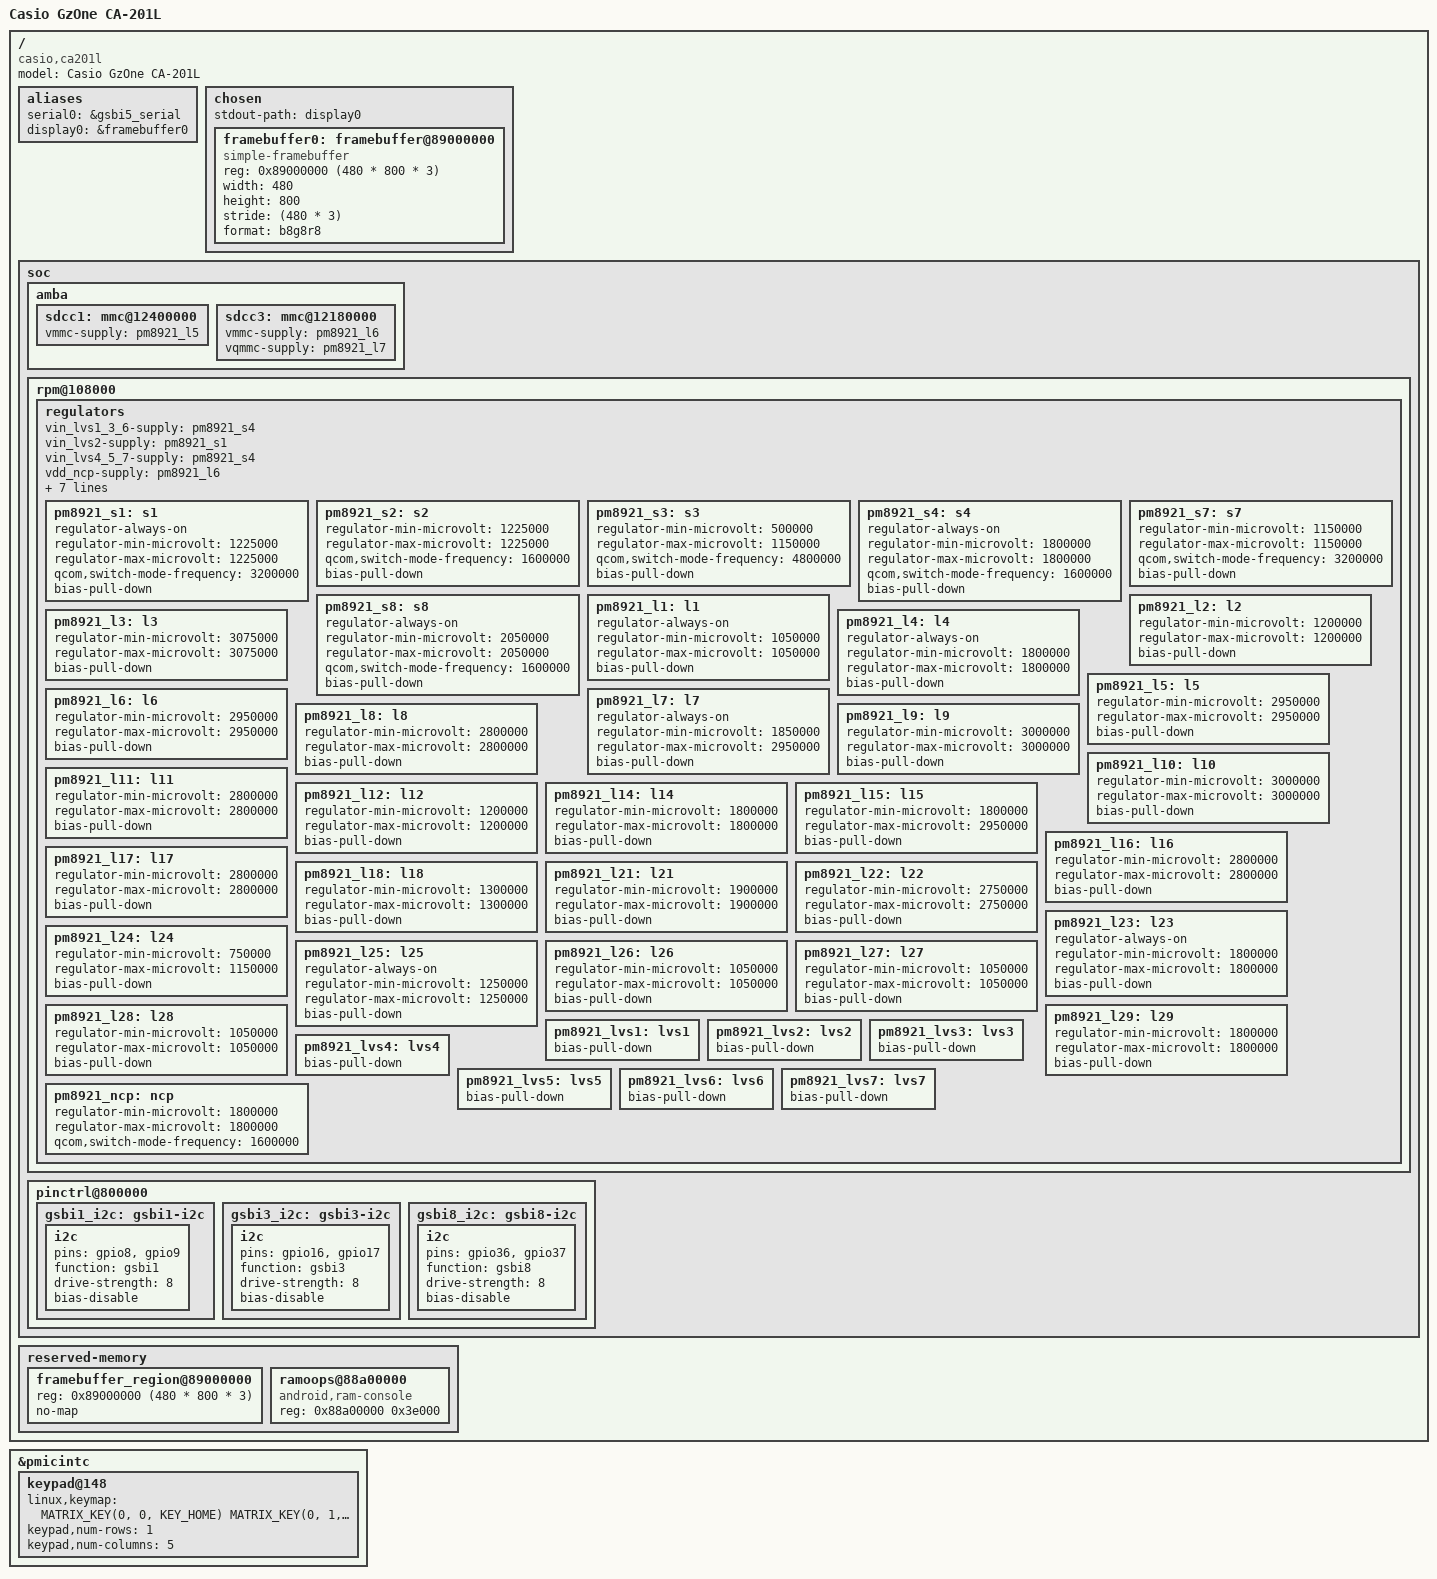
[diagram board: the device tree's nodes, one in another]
// SPDX-License-Identifier: GPL-2.0
#include <dt-bindings/input/input.h>

#include "qcom-msm8960.dtsi"

/*
 * GSBI1 is I2C on this device, remove default mapping
*/
// /delete-node/ &spi@16080000;

/ {
	model = "Casio GzOne CA-201L";
	compatible = "casio,ca201l", "qcom,msm8960";

	aliases {
		serial0 = &gsbi5_serial;
		display0 = &framebuffer0;
	};

	chosen {
		// stdout-path = "serial0:115200n8";
		stdout-path = "display0";

		#address-cells = <1>;
		#size-cells = <1>;
		ranges;

		framebuffer0: framebuffer@89000000 {
			compatible = "simple-framebuffer";
			reg = <0x89000000 (480 * 800 * 3)>;
			width = <480>;
			height = <800>;
			stride = <(480 * 3)>;
			format = "b8g8r8";
		};
	};

	/* Temporary fixed regulator */
	// vsdcc_fixed: vsdcc-regulator {
	// 	compatible = "regulator-fixed";
	// 	regulator-name = "SDCC Power";
	// 	regulator-min-microvolt = <2700000>;
	// 	regulator-max-microvolt = <2700000>;
	// 	regulator-always-on;
	// };

	soc {
		amba {
		 	/* eMMC */
			sdcc1: mmc@12400000 {
				status = "okay";
				vmmc-supply = <&pm8921_l5>;
			};

		 	/* External micro SD card */
			sdcc3: mmc@12180000 {
				status = "okay";
				vmmc-supply = <&pm8921_l6>;
				vqmmc-supply = <&pm8921_l7>;
			};
		};

		rpm@108000 {
			regulators {
				vin_lvs1_3_6-supply = <&pm8921_s4>;
				vin_lvs2-supply = <&pm8921_s1>;
				vin_lvs4_5_7-supply = <&pm8921_s4>;
				vdd_ncp-supply = <&pm8921_l6>;
				vdd_l1_l2_l12_l18-supply = <&pm8921_s4>;
				vdd_l21_l23_l29-supply = <&pm8921_s8>;
				vdd_l24-supply = <&pm8921_s1>;
				vdd_l25-supply = <&pm8921_s1>;
				vdd_l26-supply = <&pm8921_s7>;
				vdd_l27-supply = <&pm8921_s7>;
				vdd_l28-supply = <&pm8921_s7>;

				/* Buck SMPS */
				pm8921_s1: s1 {
					regulator-always-on;
					regulator-min-microvolt = <1225000>;
					regulator-max-microvolt = <1225000>;
					qcom,switch-mode-frequency = <3200000>;
					bias-pull-down;
				};

				/* changed-min-microvolt -> 1225000 */
				/* changed-max-microvolt -> 1225000 */
				pm8921_s2: s2 {
					regulator-min-microvolt = <1225000>;
					regulator-max-microvolt = <1225000>;
					qcom,switch-mode-frequency = <1600000>;
					bias-pull-down;
				};

				pm8921_s3: s3 {
					regulator-min-microvolt = <500000>;
					regulator-max-microvolt = <1150000>;
					qcom,switch-mode-frequency = <4800000>;
					bias-pull-down;
				};

				pm8921_s4: s4 {
					regulator-always-on;
					regulator-min-microvolt = <1800000>;
					regulator-max-microvolt = <1800000>;
					qcom,switch-mode-frequency = <1600000>;
					bias-pull-down;
				};

				pm8921_s7: s7 {
					regulator-min-microvolt = <1150000>;
					regulator-max-microvolt = <1150000>;
					qcom,switch-mode-frequency = <3200000>;
					bias-pull-down;
				};

				pm8921_s8: s8 {
					regulator-always-on;
					regulator-min-microvolt = <2050000>;
					regulator-max-microvolt = <2050000>;
					qcom,switch-mode-frequency = <1600000>;
					bias-pull-down;
				};

				/* PMOS LDO */
				pm8921_l1: l1 {
					regulator-always-on;
					regulator-min-microvolt = <1050000>;
					regulator-max-microvolt = <1050000>;
					bias-pull-down;
				};

				pm8921_l2: l2 {
					regulator-min-microvolt = <1200000>;
					regulator-max-microvolt = <1200000>;
					bias-pull-down;
				};

				pm8921_l3: l3 {
					regulator-min-microvolt = <3075000>;
					regulator-max-microvolt = <3075000>;
					bias-pull-down;
				};

				pm8921_l4: l4 {
					regulator-always-on;
					regulator-min-microvolt = <1800000>;
					regulator-max-microvolt = <1800000>;
					bias-pull-down;
				};

				pm8921_l5: l5 {
					regulator-min-microvolt = <2950000>;
					regulator-max-microvolt = <2950000>;
					bias-pull-down;
				};

				pm8921_l6: l6 {
					regulator-min-microvolt = <2950000>;
					regulator-max-microvolt = <2950000>;
					bias-pull-down;
				};

				pm8921_l7: l7 {
					regulator-always-on;
					regulator-min-microvolt = <1850000>;
					regulator-max-microvolt = <2950000>;
					bias-pull-down;
				};

				/* changed-max-microvolt -> 2800000 */
				pm8921_l8: l8 {
					regulator-min-microvolt = <2800000>;
					regulator-max-microvolt = <2800000>;
					bias-pull-down;
				};

				pm8921_l9: l9 {
					regulator-min-microvolt = <3000000>;
					regulator-max-microvolt = <3000000>;
					bias-pull-down;
				};

				pm8921_l10: l10 {
					regulator-min-microvolt = <3000000>;
					regulator-max-microvolt = <3000000>;
					bias-pull-down;
				};

				/* changed-min-microvolt -> 2800000 */
				/* changed-max-microvolt -> 2800000 */
				pm8921_l11: l11 {
					regulator-min-microvolt = <2800000>;
					regulator-max-microvolt = <2800000>;
					bias-pull-down;
				};

				pm8921_l12: l12 {
					regulator-min-microvolt = <1200000>;
					regulator-max-microvolt = <1200000>;
					bias-pull-down;
				};

				pm8921_l14: l14 {
					regulator-min-microvolt = <1800000>;
					regulator-max-microvolt = <1800000>;
					bias-pull-down;
				};

				pm8921_l15: l15 {
					regulator-min-microvolt = <1800000>;
					regulator-max-microvolt = <2950000>;
					bias-pull-down;
				};

				pm8921_l16: l16 {
					regulator-min-microvolt = <2800000>;
					regulator-max-microvolt = <2800000>;
					bias-pull-down;
				};

				/* changed-min-microvolt -> 2800000 */
				/* changed-max-microvolt -> 2800000 */
				pm8921_l17: l17 {
					regulator-min-microvolt = <2800000>;
					regulator-max-microvolt = <2800000>;
					bias-pull-down;
				};

				pm8921_l18: l18 {
					regulator-min-microvolt = <1300000>;
					regulator-max-microvolt = <1300000>;
					bias-pull-down;
				};

				pm8921_l21: l21 {
					regulator-min-microvolt = <1900000>;
					regulator-max-microvolt = <1900000>;
					bias-pull-down;
				};

				pm8921_l22: l22 {
					regulator-min-microvolt = <2750000>;
					regulator-max-microvolt = <2750000>;
					bias-pull-down;
				};

				pm8921_l23: l23 {
					regulator-always-on;
					regulator-min-microvolt = <1800000>;
					regulator-max-microvolt = <1800000>;
					bias-pull-down;
				};

				pm8921_l24: l24 {
					regulator-min-microvolt = <750000>;
					regulator-max-microvolt = <1150000>;
					bias-pull-down;
				};

				pm8921_l25: l25 {
					regulator-always-on;
					regulator-min-microvolt = <1250000>;
					regulator-max-microvolt = <1250000>;
					bias-pull-down;
				};

				pm8921_l26: l26 {
					regulator-min-microvolt = <1050000>;
					regulator-max-microvolt = <1050000>;
					bias-pull-down;
				};

				pm8921_l27: l27 {
					regulator-min-microvolt = <1050000>;
					regulator-max-microvolt = <1050000>;
					bias-pull-down;
				};

				pm8921_l28: l28 {
					regulator-min-microvolt = <1050000>;
					regulator-max-microvolt = <1050000>;
					bias-pull-down;
				};

				/* changed-min-microvolt -> 1800000 */
				/* changed-max-microvolt -> 1800000 */
				pm8921_l29: l29 {
					regulator-min-microvolt = <1800000>;
					regulator-max-microvolt = <1800000>;
					bias-pull-down;
				};

				/* Low Voltage Switch */
				pm8921_lvs1: lvs1 {
					bias-pull-down;
				};

				pm8921_lvs2: lvs2 {
					bias-pull-down;
				};

				pm8921_lvs3: lvs3 {
					bias-pull-down;
				};

				pm8921_lvs4: lvs4 {
					bias-pull-down;
				};

				pm8921_lvs5: lvs5 {
					bias-pull-down;
				};

				pm8921_lvs6: lvs6 {
					bias-pull-down;
				};

				pm8921_lvs7: lvs7 {
					bias-pull-down;
				};

				pm8921_ncp: ncp {
					regulator-min-microvolt = <1800000>;
					regulator-max-microvolt = <1800000>;
					qcom,switch-mode-frequency = <1600000>;
				};
			};
		};

		pinctrl@800000 {
			// gpio {
			// 	pins = "gpio106";
			// 	function = "gpio";

			// 	drive-strength = <2>;
			// 	bias-disable;
			// };

			gsbi1_i2c: gsbi1-i2c {
				i2c {
					pins = "gpio8", "gpio9";
					function = "gsbi1";

					drive-strength = <8>;
					bias-disable;
				};
			};

			gsbi3_i2c: gsbi3-i2c {
				i2c {
					pins = "gpio16", "gpio17";
					function = "gsbi3";

					drive-strength = <8>;
					bias-disable;
				};
			};

			gsbi8_i2c: gsbi8-i2c {
				i2c {
					pins = "gpio36", "gpio37";
					function = "gsbi8";

					drive-strength = <8>;
					bias-disable;
				};
			};

			// gsbi10_i2c: gsbi10-i2c {
			// 	i2c {
			// 		pins = "gpio73", "gpio74";
			// 		function = "gsbi10";

			// 		drive-strength = <8>;
			// 		bias-disable;
			// 	};
			// };

			// gsbi12_i2c: gsbi12-i2c {
			// 	i2c {
			// 		pins = "gpio44", "gpio45";
			// 		function = "gsbi12";

			// 		drive-strength = <8>;
			// 		bias-disable;
			// 	};
			// };
		};

		/* gsbi1: i2c - st21nfca, GPIO: 8, 9, 106 (ST21NFCA_WAKEUP) */
		// gsbi1: gsbi@16000000 {
		// 	qcom,mode = <GSBI_PROT_I2C>;

		// 	i2c@16080000 {
		// 		clock-frequency = <400000>;
		// 		pinctrl-0 = <&i2c1_pins>;
		// 		pinctrl-names = "default";

		// 		/* 1-0001: st21nfca */
		// 		nfc@1 {
		// 			compatible = "st,st21nfca-i2c";
		// 			reg = <0x1>;

		// 			interrupt-parent = <&msmgpio>;
		// 			interrupts = <106 IRQ_TYPE_LEVEL_LOW>;
		// 			enable-gpios = <&msmgpio 106 GPIO_ACTIVE_HIGH>;

		// 			ese-present;
		// 			uicc-present;
		// 		};
		// 	};
		// };

		/* gsbi3: i2c - cyttsp, mxt_device, mxt224e, backlight (rev3, rev >= 8), GPIO: 16 (SDA), 17 (SCL) */
		// gsbi3: gsbi@16200000 {
		// 	qcom,mode = <GSBI_PROT_I2C>;

		// 	i2c@16280000 {
		// 		clock-frequency = <100000>;
		// 		pinctrl-0 = <&i2c3_pins>;
		// 		pinctrl-names = "default";

		// 		/* 3-0038: lm3530 */
		// 		backlight@38 {
		// 			compatible = "ti,lm3530";
		// 			enable-gpios = <&pm8921_gpio 24 GPIO_ACTIVE_HIGH>;
		// 			default-brightness = <0x45>;
		// 			max-brightness = <0x7f>;
		// 			ramp-up-ms = <8>;
		// 			ramp-down-ms = <8>;
		// 			ti,current-limit = /bits/ 8 <0x15>; // 22.5 mA, raw register value
		// 			ti,led-mode = /bits/ 8 <0x02>; // PWM mode, Casio driver also do not touch ALS register
		// 			ti,linear-mapping-mode = /bits/ 8 <0>;
		// 		};

		// 		/* 3-004a: mXT224E */
		// 		touchscreen@4a {
		// 			compatible = "atmel,maxtouch";
		// 			reg = <0x4a>;
		// 			interrupt-parent = <&msmgpio>;
		// 			interrupts = <11 IRQ_TYPE_EDGE_FALLING>;
		// 			reset-gpios = <&msmgpio 50 GPIO_ACTIVE_LOW>;
		// 			atmel,wakeup-method = <ATMEL_MXT_WAKEUP_GPIO>;
		// 			wake-gpios = <&pm8921 17 GPIO_ACTIVE_LOW>;
		// 		};
		// 	};
			
		// };

		/* gsbi4: i2c - camera main, camera sub */
		// mt9m113, mt9e013 - no drivers
		// gsbi4: gsbi@16300000 { // GSBI4
		// 	qcom,mode = <GSBI_PROT_I2C>;

		// 	i2c@16380000 {
		// 		clock-frequency = <360000>;
		// 		pinctrl-0 = <&i2c4_pins>;
		// 		pinctrl-names = "default";

		// 		/* 4-000d: mt9e013_act */
		// 		/* 4-0036: mt9e013 */
		// 		/* 4-003c: mt9m113 */
		// 	};
		// };

		/* gsbi5: uart (GPIO: 22, 23, 24, 25) */
		// gsbi5: gsbi@16400000 {
		// 	status = "okay";
		// 	qcom,mode = <GSBI_PROT_I2C_UART>;
		// 	serial@16440000 {
		// 		status = "okay";
		// 	};
		// };

		/* gsbi8: i2c - yda160, es310 (GPIO: 36, 37) */
		// es310, yda160 - no drivers
		// gsbi8: gsbi@1a000000 { // GSBI8
		// 	qcom,mode = <GSBI_PROT_I2C>;

		// 	i2c@1a080000 {
		// 		clock-frequency = <100000>;
		// 		pinctrl-0 = <&i2c8_pins>;
		// 		pinctrl-names = "default";

		// 		/* 8-003e: audience_es310 */
		// 		/* 8-006c: yamaha_yda160 */
		// 	};
		// };

		/* gsbi10: i2c - sii, msm_isa1200, liquid_io_expander (GPIO: 73 (SDA), 74 (SCL)) */

	};

	reserved-memory {
		#address-cells = <1>;
		#size-cells = <1>;
		ranges;

		framebuffer_region@89000000 {
			reg = <0x89000000 (480 * 800 * 3)>;
			no-map;
		};

		ramoops@88a00000 {
			// compatible = "ramoops";
			compatible = "android,ram-console";
			reg = <0x88a00000 0x3e000>;
			// console-size = <0x3e000>;
			// record-size = <0x3e000>;
			// ftrace-size = <0x0>;
			// pmsg-size = <0x3e000>;
			// ecc-size = <0x10>;
		};
	};
};

&pmicintc {
	keypad@148 {
		// KEY_TACTILE: only existing in this device
		linux,keymap = <
			MATRIX_KEY(0, 0, KEY_HOME)
			MATRIX_KEY(0, 1, KEY_VOLUMEUP)
			MATRIX_KEY(0, 2, KEY_VOLUMEDOWN)
			>;
		keypad,num-rows = <1>;
		keypad,num-columns = <5>;
	};
};

// &pm8921_gpio {
// 	pinctrl-0 = <&pm8921_gpio_default>;
// 	pinctrl-names = "default";

// 	pm8921_gpio_default: pm8921-gpio-default {
// 	/* gpio6: output_vin, 1, PM_GPIO_VIN_VPH
// 	   gpio7: output, 1
// 	   gpio16: output, 0
// 	   gpio18: output, 0 (top_spk_pamp)
// 	   gpio19: output, 0 (bottom_spk_pamp)
// 	   gpio38: input, PM_GPIO_PULL_UP_30
// 	   gpio17: output, 0
// 	   gpio21: output_vin, 1, PM_GPIO_VIN_VPH
// 	   gpio22: disable
// 	   gpio36: output, 1
// 	   gpio38: JACK_DETECT_GPIO

// 	   gpio24: output, 1 (LG4573B)
// 	   gpio43: output, 1 (LG4573B)

// 	   gpio42: output, 0 (MT9D115_PMGPIO_CAM2_V_EN1)
// 	   gpio14: output, 0
// 	   gpio25: (IMX111_PMGPIO_CAM_V_EN2)

// 	   */
// 	};
// };

// // lg4573: only SPI driver exist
